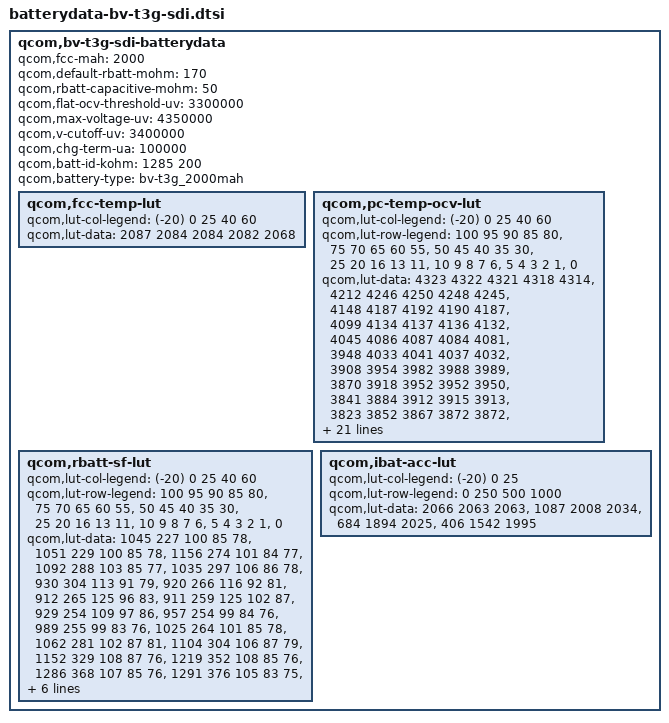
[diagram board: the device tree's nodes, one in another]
/* Copyright (c) 2013-2014, The Linux Foundation. All rights reserved.
 *
 * This program is free software; you can redistribute it and/or modify
 * it under the terms of the GNU General Public License version 2 and
 * only version 2 as published by the Free Software Foundation.
 *
 * This program is distributed in the hope that it will be useful,
 * but WITHOUT ANY WARRANTY; without even the implied warranty of
 * MERCHANTABILITY or FITNESS FOR A PARTICULAR PURPOSE.  See the
 * GNU General Public License for more details.
 */

qcom,bv-t3g-sdi-batterydata {
	qcom,fcc-mah = <2000>;
	qcom,default-rbatt-mohm = <170>;
	qcom,rbatt-capacitive-mohm = <50>;
	qcom,flat-ocv-threshold-uv = <3300000>;
	qcom,max-voltage-uv = <4350000>;
	qcom,v-cutoff-uv = <3400000>;
	qcom,chg-term-ua = <100000>;
	qcom,batt-id-kohm = <1285 200>;
	qcom,battery-type = "bv-t3g_2000mah";

	qcom,fcc-temp-lut {
		qcom,lut-col-legend = <(-20) 0 25 40 60>;
		qcom,lut-data = <2087 2084 2084 2082 2068>;
	};

	qcom,pc-temp-ocv-lut {
		qcom,lut-col-legend = <(-20) 0 25 40 60>;
		qcom,lut-row-legend = <100 95 90 85 80>,
				<75 70 65 60 55>,
				<50 45 40 35 30>,
				<25 20 16 13 11>,
				<10 9 8 7 6>,
				<5 4 3 2 1>,
				<0>;
		qcom,lut-data = <4323 4322 4321 4318 4314>,
				<4212 4246 4250 4248 4245>,
				<4148 4187 4192 4190 4187>,
				<4099 4134 4137 4136 4132>,
				<4045 4086 4087 4084 4081>,
				<3948 4033 4041 4037 4032>,
				<3908 3954 3982 3988 3989>,
				<3870 3918 3952 3952 3950>,
				<3841 3884 3912 3915 3913>,
				<3823 3852 3867 3872 3872>,
				<3809 3826 3833 3833 3833>,
				<3796 3805 3810 3811 3810>,
				<3784 3790 3793 3794 3792>,
				<3771 3781 3780 3780 3779>,
				<3757 3772 3772 3768 3762>,
				<3743 3761 3763 3756 3743>,
				<3728 3742 3747 3738 3724>,
				<3713 3719 3720 3711 3698>,
				<3699 3705 3693 3685 3673>,
				<3686 3699 3689 3682 3671>,
				<3680 3697 3688 3681 3670>,
				<3671 3694 3687 3680 3669>,
				<3662 3691 3686 3679 3668>,
				<3650 3689 3685 3678 3667>,
				<3634 3684 3682 3674 3662>,
				<3609 3674 3672 3658 3641>,
				<3578 3646 3635 3614 3596>,
				<3534 3597 3577 3551 3532>,
				<3466 3513 3484 3464 3441>,
				<3344 3382 3339 3330 3283>,
				<3000 3000 3000 3000 3000>;
	};

	qcom,rbatt-sf-lut {
		qcom,lut-col-legend = <(-20) 0 25 40 60>;
		qcom,lut-row-legend = <100 95 90 85 80>,
				<75 70 65 60 55>,
				<50 45 40 35 30>,
				<25 20 16 13 11>,
				<10 9 8 7 6>,
				<5 4 3 2 1>,
				<0>;
		qcom,lut-data = <1045 227 100 85 78>,
				<1051 229 100 85 78>,
				<1156 274 101 84 77>,
				<1092 288 103 85 77>,
				<1035 297 106 86 78>,
				<930 304 113 91 79>,
				<920 266 116 92 81>,
				<912 265 125 96 83>,
				<911 259 125 102 87>,
				<929 254 109 97 86>,
				<957 254 99 84 76>,
				<989 255 99 83 76>,
				<1025 264 101 85 78>,
				<1062 281 102 87 81>,
				<1104 304 106 87 79>,
				<1152 329 108 87 76>,
				<1219 352 108 85 76>,
				<1286 368 107 85 76>,
				<1291 376 105 83 75>,
				<1430 399 106 84 76>,
				<1538 415 108 86 77>,
				<1654 432 111 87 78>,
				<1801 456 115 90 79>,
				<1966 484 119 92 81>,
				<2181 515 126 94 82>,
				<2523 550 131 93 80>,
				<2975 578 127 92 79>,
				<3678 620 132 96 83>,
				<4959 714 151 105 92>,
				<9919 1427 301 130 184>;
	};

	qcom,ibat-acc-lut {
		qcom,lut-col-legend = <(-20) 0 25>;
		qcom,lut-row-legend = <0 250 500 1000>;
		qcom,lut-data = <2066 2063 2063>,
				<1087 2008 2034>,
				<684 1894 2025>,
				<406 1542 1995>;
	};
};
